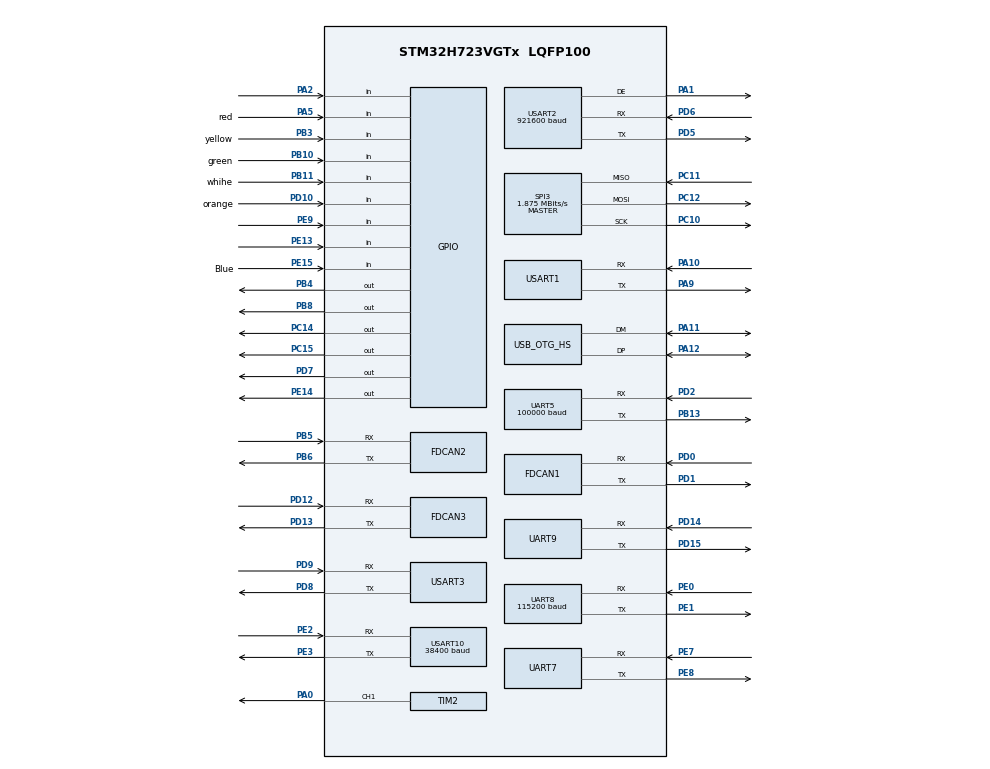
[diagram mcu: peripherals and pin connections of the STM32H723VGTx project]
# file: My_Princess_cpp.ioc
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CORTEX_M7.default_mode_Activation=1
Dma.Request0=USART2_RX
Dma.Request1=USART10_TX
Dma.Request10=TIM2_CH1
Dma.Request2=UART8_RX
Dma.Request3=UART5_RX
Dma.Request4=USART10_RX
Dma.Request5=UART9_RX
Dma.Request6=UART9_TX
Dma.Request7=UART8_TX
Dma.Request8=UART7_RX
Dma.Request9=UART7_TX
Dma.TIM2_CH1.10.Direction=DMA_MEMORY_TO_PERIPH
Dma.TIM2_CH1.10.EventEnable=DISABLE
Dma.TIM2_CH1.10.FIFOMode=DMA_FIFOMODE_DISABLE
Dma.TIM2_CH1.10.Instance=DMA2_Stream2
Dma.TIM2_CH1.10.MemDataAlignment=DMA_MDATAALIGN_WORD
Dma.TIM2_CH1.10.MemInc=DMA_MINC_ENABLE
Dma.TIM2_CH1.10.Mode=DMA_NORMAL
Dma.TIM2_CH1.10.PeriphDataAlignment=DMA_PDATAALIGN_WORD
Dma.TIM2_CH1.10.PeriphInc=DMA_PINC_DISABLE
Dma.TIM2_CH1.10.Polarity=HAL_DMAMUX_REQ_GEN_RISING
Dma.TIM2_CH1.10.Priority=DMA_PRIORITY_LOW
Dma.TIM2_CH1.10.RequestNumber=1
Dma.TIM2_CH1.10.SignalID=NONE
Dma.TIM2_CH1.10.SyncEnable=DISABLE
Dma.TIM2_CH1.10.SyncPolarity=HAL_DMAMUX_SYNC_NO_EVENT
Dma.TIM2_CH1.10.SyncRequestNumber=1
Dma.TIM2_CH1.10.SyncSignalID=NONE
Dma.UART5_RX.3.Direction=DMA_PERIPH_TO_MEMORY
Dma.UART5_RX.3.EventEnable=DISABLE
Dma.UART5_RX.3.FIFOMode=DMA_FIFOMODE_DISABLE
Dma.UART5_RX.3.Instance=DMA1_Stream0
Dma.UART5_RX.3.MemDataAlignment=DMA_MDATAALIGN_BYTE
Dma.UART5_RX.3.MemInc=DMA_MINC_ENABLE
Dma.UART5_RX.3.Mode=DMA_CIRCULAR
Dma.UART5_RX.3.PeriphDataAlignment=DMA_PDATAALIGN_BYTE
Dma.UART5_RX.3.PeriphInc=DMA_PINC_DISABLE
Dma.UART5_RX.3.Polarity=HAL_DMAMUX_REQ_GEN_RISING
Dma.UART5_RX.3.Priority=DMA_PRIORITY_HIGH
Dma.UART5_RX.3.RequestNumber=1
Dma.UART5_RX.3.SignalID=NONE
Dma.UART5_RX.3.SyncEnable=DISABLE
Dma.UART5_RX.3.SyncPolarity=HAL_DMAMUX_SYNC_NO_EVENT
Dma.UART5_RX.3.SyncRequestNumber=1
Dma.UART5_RX.3.SyncSignalID=NONE
Dma.UART7_RX.8.Direction=DMA_PERIPH_TO_MEMORY
Dma.UART7_RX.8.EventEnable=DISABLE
Dma.UART7_RX.8.FIFOMode=DMA_FIFOMODE_DISABLE
Dma.UART7_RX.8.Instance=DMA2_Stream0
Dma.UART7_RX.8.MemDataAlignment=DMA_MDATAALIGN_BYTE
Dma.UART7_RX.8.MemInc=DMA_MINC_ENABLE
Dma.UART7_RX.8.Mode=DMA_CIRCULAR
Dma.UART7_RX.8.PeriphDataAlignment=DMA_PDATAALIGN_BYTE
Dma.UART7_RX.8.PeriphInc=DMA_PINC_DISABLE
Dma.UART7_RX.8.Polarity=HAL_DMAMUX_REQ_GEN_RISING
Dma.UART7_RX.8.Priority=DMA_PRIORITY_LOW
Dma.UART7_RX.8.RequestNumber=1
Dma.UART7_RX.8.SignalID=NONE
Dma.UART7_RX.8.SyncEnable=DISABLE
Dma.UART7_RX.8.SyncPolarity=HAL_DMAMUX_SYNC_NO_EVENT
Dma.UART7_RX.8.SyncRequestNumber=1
Dma.UART7_RX.8.SyncSignalID=NONE
Dma.UART7_TX.9.Direction=DMA_MEMORY_TO_PERIPH
Dma.UART7_TX.9.EventEnable=DISABLE
Dma.UART7_TX.9.FIFOMode=DMA_FIFOMODE_DISABLE
Dma.UART7_TX.9.Instance=DMA2_Stream1
Dma.UART7_TX.9.MemDataAlignment=DMA_MDATAALIGN_BYTE
Dma.UART7_TX.9.MemInc=DMA_MINC_ENABLE
Dma.UART7_TX.9.Mode=DMA_NORMAL
Dma.UART7_TX.9.PeriphDataAlignment=DMA_PDATAALIGN_BYTE
Dma.UART7_TX.9.PeriphInc=DMA_PINC_DISABLE
Dma.UART7_TX.9.Polarity=HAL_DMAMUX_REQ_GEN_RISING
Dma.UART7_TX.9.Priority=DMA_PRIORITY_LOW
Dma.UART7_TX.9.RequestNumber=1
Dma.UART7_TX.9.SignalID=NONE
Dma.UART7_TX.9.SyncEnable=DISABLE
Dma.UART7_TX.9.SyncPolarity=HAL_DMAMUX_SYNC_NO_EVENT
Dma.UART7_TX.9.SyncRequestNumber=1
Dma.UART7_TX.9.SyncSignalID=NONE
Dma.UART8_RX.2.Direction=DMA_PERIPH_TO_MEMORY
Dma.UART8_RX.2.EventEnable=DISABLE
Dma.UART8_RX.2.FIFOMode=DMA_FIFOMODE_DISABLE
Dma.UART8_RX.2.Instance=DMA1_Stream3
Dma.UART8_RX.2.MemDataAlignment=DMA_MDATAALIGN_BYTE
Dma.UART8_RX.2.MemInc=DMA_MINC_ENABLE
Dma.UART8_RX.2.Mode=DMA_CIRCULAR
Dma.UART8_RX.2.PeriphDataAlignment=DMA_PDATAALIGN_BYTE
Dma.UART8_RX.2.PeriphInc=DMA_PINC_DISABLE
Dma.UART8_RX.2.Polarity=HAL_DMAMUX_REQ_GEN_RISING
Dma.UART8_RX.2.Priority=DMA_PRIORITY_LOW
Dma.UART8_RX.2.RequestNumber=1
Dma.UART8_RX.2.SignalID=NONE
Dma.UART8_RX.2.SyncEnable=DISABLE
Dma.UART8_RX.2.SyncPolarity=HAL_DMAMUX_SYNC_NO_EVENT
Dma.UART8_RX.2.SyncRequestNumber=1
Dma.UART8_RX.2.SyncSignalID=NONE
Dma.UART8_TX.7.Direction=DMA_MEMORY_TO_PERIPH
Dma.UART8_TX.7.EventEnable=DISABLE
Dma.UART8_TX.7.FIFOMode=DMA_FIFOMODE_DISABLE
Dma.UART8_TX.7.Instance=DMA1_Stream7
Dma.UART8_TX.7.MemDataAlignment=DMA_MDATAALIGN_BYTE
Dma.UART8_TX.7.MemInc=DMA_MINC_ENABLE
Dma.UART8_TX.7.Mode=DMA_NORMAL
Dma.UART8_TX.7.PeriphDataAlignment=DMA_PDATAALIGN_BYTE
Dma.UART8_TX.7.PeriphInc=DMA_PINC_DISABLE
Dma.UART8_TX.7.Polarity=HAL_DMAMUX_REQ_GEN_RISING
Dma.UART8_TX.7.Priority=DMA_PRIORITY_LOW
Dma.UART8_TX.7.RequestNumber=1
Dma.UART8_TX.7.SignalID=NONE
Dma.UART8_TX.7.SyncEnable=DISABLE
Dma.UART8_TX.7.SyncPolarity=HAL_DMAMUX_SYNC_NO_EVENT
Dma.UART8_TX.7.SyncRequestNumber=1
Dma.UART8_TX.7.SyncSignalID=NONE
Dma.UART9_RX.5.Direction=DMA_PERIPH_TO_MEMORY
Dma.UART9_RX.5.EventEnable=DISABLE
Dma.UART9_RX.5.FIFOMode=DMA_FIFOMODE_DISABLE
Dma.UART9_RX.5.Instance=DMA1_Stream5
Dma.UART9_RX.5.MemDataAlignment=DMA_MDATAALIGN_BYTE
Dma.UART9_RX.5.MemInc=DMA_MINC_ENABLE
Dma.UART9_RX.5.Mode=DMA_CIRCULAR
Dma.UART9_RX.5.PeriphDataAlignment=DMA_PDATAALIGN_BYTE
Dma.UART9_RX.5.PeriphInc=DMA_PINC_DISABLE
Dma.UART9_RX.5.Polarity=HAL_DMAMUX_REQ_GEN_RISING
Dma.UART9_RX.5.Priority=DMA_PRIORITY_LOW
Dma.UART9_RX.5.RequestNumber=1
Dma.UART9_RX.5.SignalID=NONE
Dma.UART9_RX.5.SyncEnable=DISABLE
Dma.UART9_RX.5.SyncPolarity=HAL_DMAMUX_SYNC_NO_EVENT
Dma.UART9_RX.5.SyncRequestNumber=1
Dma.UART9_RX.5.SyncSignalID=NONE
Dma.UART9_TX.6.Direction=DMA_MEMORY_TO_PERIPH
Dma.UART9_TX.6.EventEnable=DISABLE
Dma.UART9_TX.6.FIFOMode=DMA_FIFOMODE_DISABLE
Dma.UART9_TX.6.Instance=DMA1_Stream6
Dma.UART9_TX.6.MemDataAlignment=DMA_MDATAALIGN_BYTE
Dma.UART9_TX.6.MemInc=DMA_MINC_ENABLE
Dma.UART9_TX.6.Mode=DMA_NORMAL
Dma.UART9_TX.6.PeriphDataAlignment=DMA_PDATAALIGN_BYTE
Dma.UART9_TX.6.PeriphInc=DMA_PINC_DISABLE
Dma.UART9_TX.6.Polarity=HAL_DMAMUX_REQ_GEN_RISING
Dma.UART9_TX.6.Priority=DMA_PRIORITY_LOW
Dma.UART9_TX.6.RequestNumber=1
Dma.UART9_TX.6.SignalID=NONE
Dma.UART9_TX.6.SyncEnable=DISABLE
Dma.UART9_TX.6.SyncPolarity=HAL_DMAMUX_SYNC_NO_EVENT
Dma.UART9_TX.6.SyncRequestNumber=1
Dma.UART9_TX.6.SyncSignalID=NONE
Dma.USART10_RX.4.Direction=DMA_PERIPH_TO_MEMORY
Dma.USART10_RX.4.EventEnable=DISABLE
Dma.USART10_RX.4.FIFOMode=DMA_FIFOMODE_DISABLE
Dma.USART10_RX.4.Instance=DMA1_Stream4
Dma.USART10_RX.4.MemDataAlignment=DMA_MDATAALIGN_BYTE
Dma.USART10_RX.4.MemInc=DMA_MINC_ENABLE
Dma.USART10_RX.4.Mode=DMA_NORMAL
Dma.USART10_RX.4.PeriphDataAlignment=DMA_PDATAALIGN_BYTE
Dma.USART10_RX.4.PeriphInc=DMA_PINC_DISABLE
Dma.USART10_RX.4.Polarity=HAL_DMAMUX_REQ_GEN_RISING
Dma.USART10_RX.4.Priority=DMA_PRIORITY_LOW
Dma.USART10_RX.4.RequestNumber=1
Dma.USART10_RX.4.SignalID=NONE
Dma.USART10_RX.4.SyncEnable=DISABLE
Dma.USART10_RX.4.SyncPolarity=HAL_DMAMUX_SYNC_NO_EVENT
Dma.USART10_RX.4.SyncRequestNumber=1
Dma.USART10_RX.4.SyncSignalID=NONE
Dma.USART10_TX.1.Direction=DMA_MEMORY_TO_PERIPH
Dma.USART10_TX.1.EventEnable=DISABLE
Dma.USART10_TX.1.FIFOMode=DMA_FIFOMODE_DISABLE
Dma.USART10_TX.1.Instance=DMA1_Stream2
Dma.USART10_TX.1.MemDataAlignment=DMA_MDATAALIGN_BYTE
Dma.USART10_TX.1.MemInc=DMA_MINC_ENABLE
Dma.USART10_TX.1.Mode=DMA_NORMAL
Dma.USART10_TX.1.PeriphDataAlignment=DMA_PDATAALIGN_BYTE
Dma.USART10_TX.1.PeriphInc=DMA_PINC_DISABLE
Dma.USART10_TX.1.Polarity=HAL_DMAMUX_REQ_GEN_RISING
Dma.USART10_TX.1.Priority=DMA_PRIORITY_MEDIUM
Dma.USART10_TX.1.RequestNumber=1
Dma.USART10_TX.1.SignalID=NONE
Dma.USART10_TX.1.SyncEnable=DISABLE
Dma.USART10_TX.1.SyncPolarity=HAL_DMAMUX_SYNC_NO_EVENT
Dma.USART10_TX.1.SyncRequestNumber=1
Dma.USART10_TX.1.SyncSignalID=NONE
Dma.USART2_RX.0.Direction=DMA_PERIPH_TO_MEMORY
Dma.USART2_RX.0.EventEnable=DISABLE
Dma.USART2_RX.0.FIFOMode=DMA_FIFOMODE_DISABLE
Dma.USART2_RX.0.Instance=DMA1_Stream1
Dma.USART2_RX.0.MemDataAlignment=DMA_MDATAALIGN_BYTE
Dma.USART2_RX.0.MemInc=DMA_MINC_ENABLE
Dma.USART2_RX.0.Mode=DMA_CIRCULAR
Dma.USART2_RX.0.PeriphDataAlignment=DMA_PDATAALIGN_BYTE
Dma.USART2_RX.0.PeriphInc=DMA_PINC_DISABLE
Dma.USART2_RX.0.Polarity=HAL_DMAMUX_REQ_GEN_RISING
Dma.USART2_RX.0.Priority=DMA_PRIORITY_HIGH
Dma.USART2_RX.0.RequestNumber=1
Dma.USART2_RX.0.SignalID=NONE
Dma.USART2_RX.0.SyncEnable=DISABLE
Dma.USART2_RX.0.SyncPolarity=HAL_DMAMUX_SYNC_NO_EVENT
Dma.USART2_RX.0.SyncRequestNumber=1
Dma.USART2_RX.0.SyncSignalID=NONE
FDCAN1.CalculateBaudRateNominal=1000000
FDCAN1.CalculateTimeBitNominal=1000
FDCAN1.CalculateTimeQuantumNominal=25.0
FDCAN1.DataPrescaler=3
FDCAN1.DataSyncJumpWidth=10
FDCAN1.DataTimeSeg1=29
FDCAN1.DataTimeSeg2=5
FDCAN1.NominalPrescaler=3
FDCAN1.NominalSyncJumpWidth=10
FDCAN1.NominalTimeSeg1=29
FDCAN1.NominalTimeSeg2=10
FDCAN1.RxFifo0ElmtsNbr=8
FDCAN1.StdFiltersNbr=1
FDCAN1.TxFifoQueueElmtsNbr=8
FDCAN2.AutoRetransmission=DISABLE
FDCAN2.CalculateBaudRateNominal=1000000
FDCAN2.CalculateTimeBitNominal=1000
FDCAN2.CalculateTimeQuantumNominal=25.0
FDCAN2.DataPrescaler=3
FDCAN2.DataSyncJumpWidth=10
FDCAN2.DataTimeSeg1=29
FDCAN2.DataTimeSeg2=5
FDCAN2.ExtFiltersNbr=1
FDCAN2.MessageRAMOffset=128
FDCAN2.NominalPrescaler=3
FDCAN2.NominalSyncJumpWidth=10
FDCAN2.NominalTimeSeg1=29
FDCAN2.NominalTimeSeg2=10
FDCAN2.RxFifo0ElmtsNbr=16
FDCAN2.RxFifo1ElmtsNbr=16
FDCAN2.StdFiltersNbr=0
FDCAN2.TxFifoQueueElmtsNbr=8
FDCAN3.CalculateBaudRateNominal=1000000
FDCAN3.CalculateTimeBitNominal=1000
FDCAN3.CalculateTimeQuantumNominal=25.0
FDCAN3.DataPrescaler=3
FDCAN3.DataSyncJumpWidth=10
FDCAN3.DataTimeSeg1=29
FDCAN3.DataTimeSeg2=5
FDCAN3.MessageRAMOffset=512
FDCAN3.NominalPrescaler=3
FDCAN3.NominalSyncJumpWidth=10
FDCAN3.NominalTimeSeg1=29
FDCAN3.NominalTimeSeg2=10
FDCAN3.RxFifo0ElmtsNbr=8
FDCAN3.StdFiltersNbr=1
FDCAN3.TxFifoQueueElmtsNbr=8
FREERTOS.Tasks01=CHASSIS_TASK,24,512,chassis_task,As weak,NULL,Static,CHASSIS_TASKBuffer,CHASSIS_TASKControlBlock;USART_TASK,24,512,usart_task,As weak,NULL,Static,USART_TASKBuffer,USART_TASKControlBlock;LIFT_TASK,24,512,lift_task,As weak,NULL,Static,LIFT_TASKBuffer,LIFT_TASKControlBlock;PLAN_ROUTE,26,512,plan_route,As weak,NULL,Static,PLAN_ROUTEBuffer,PLAN_ROUTEControlBlock;FTMTask,24,512,ftm_task,As weak,NULL,Static,FTMTaskBuffer,FTMTaskControlBlock;WUQIQUTask,24,512,wuqiqu_task,As weak,NULL,Static,WUQIQUTaskBuffer,WUQIQUTaskControlBlock;CONBAT_TASK,24,512,conbat_task,As weak,NULL,Static,CONBAT_TASKBuffer,CONBAT_TASKControlBlock;LEDTask,24,256,led_task,As weak,NULL,Static,LEDTaskBuffer,LEDTaskControlBlock
Mcu.Family=STM32H7
Mcu.Name=STM32H723VGTx
Mcu.Package=LQFP100
NVIC.DMA1_Stream0_IRQn=true\:5\:0\:false\:false\:true\:true\:false\:true\:true
NVIC.DMA1_Stream1_IRQn=true\:5\:0\:false\:false\:true\:true\:false\:true\:true
NVIC.DMA1_Stream2_IRQn=true\:5\:0\:false\:false\:true\:true\:false\:true\:true
NVIC.DMA1_Stream3_IRQn=true\:5\:0\:false\:false\:true\:true\:false\:true\:true
NVIC.DMA1_Stream4_IRQn=true\:5\:0\:false\:false\:true\:true\:false\:true\:true
NVIC.DMA1_Stream5_IRQn=true\:5\:0\:false\:false\:true\:true\:false\:true\:true
NVIC.DMA1_Stream6_IRQn=true\:5\:0\:false\:false\:true\:true\:false\:true\:true
NVIC.DMA1_Stream7_IRQn=true\:5\:0\:false\:false\:true\:true\:false\:true\:true
NVIC.DMA2_Stream0_IRQn=true\:5\:0\:false\:false\:true\:true\:false\:true\:true
NVIC.DMA2_Stream1_IRQn=true\:5\:0\:false\:false\:true\:true\:false\:true\:true
NVIC.DMA2_Stream2_IRQn=true\:5\:0\:false\:false\:true\:true\:false\:true\:true
NVIC.FDCAN1_IT0_IRQn=true\:5\:0\:false\:false\:true\:true\:true\:true\:true
NVIC.FDCAN2_IT0_IRQn=true\:5\:0\:false\:false\:true\:true\:true\:true\:true
NVIC.FDCAN2_IT1_IRQn=true\:5\:0\:false\:false\:true\:true\:true\:true\:true
NVIC.FDCAN3_IT0_IRQn=true\:5\:0\:false\:false\:true\:true\:true\:true\:true
NVIC.OTG_HS_IRQn=true\:5\:0\:false\:false\:true\:true\:false\:true\:true
NVIC.PriorityGroup=NVIC_PRIORITYGROUP_4
NVIC.TIM6_DAC_IRQn=true\:15\:0\:false\:false\:true\:false\:false\:true\:true
NVIC.TimeBase=TIM6_DAC_IRQn
NVIC.TimeBaseIP=TIM6
NVIC.UART5_IRQn=true\:5\:0\:false\:false\:true\:true\:true\:true\:true
NVIC.UART7_IRQn=true\:5\:0\:false\:false\:true\:true\:true\:true\:true
NVIC.UART8_IRQn=true\:5\:0\:false\:false\:true\:true\:true\:true\:true
NVIC.UART9_IRQn=true\:5\:0\:false\:false\:true\:true\:true\:true\:true
NVIC.USART10_IRQn=true\:5\:0\:false\:false\:true\:true\:true\:true\:true
NVIC.USART2_IRQn=true\:5\:0\:false\:false\:true\:true\:true\:true\:true
PA0.Signal=S_TIM2_CH1_ETR
PA1.Mode=Hardware Flow Control (RS485)
PA1.Signal=USART2_DE
PA10.Mode=Asynchronous
PA10.Signal=USART1_RX
PA11.Mode=Device_Only_FS
PA11.Signal=USB_OTG_HS_DM
PA12.Mode=Device_Only_FS
PA12.Signal=USB_OTG_HS_DP
PA13(JTMS/SWDIO).Mode=Serial_Wire
PA13(JTMS/SWDIO).Signal=DEBUG_JTMS-SWDIO
PA14(JTCK/SWCLK).Mode=Serial_Wire
PA14(JTCK/SWCLK).Signal=DEBUG_JTCK-SWCLK
PA2.GPIO_PuPd=GPIO_PULLUP
PA2.Signal=GPIO_Input
PA5.GPIO_Label=red
PA5.GPIO_PuPd=GPIO_PULLUP
PA5.Signal=GPIO_Input
PA9.Mode=Asynchronous
PA9.Signal=USART1_TX
PB10.GPIO_Label=green
PB10.GPIO_PuPd=GPIO_PULLUP
PB10.Signal=GPIO_Input
PB11.GPIO_Label=whihe
PB11.GPIO_PuPd=GPIO_PULLUP
PB11.Signal=GPIO_Input
PB13.Mode=Asynchronous
PB13.Signal=UART5_TX
PB3(JTDO/TRACESWO).GPIO_Label=yellow
PB3(JTDO/TRACESWO).GPIO_PuPd=GPIO_PULLUP
PB3(JTDO/TRACESWO).Signal=GPIO_Input
PB4(NJTRST).Signal=GPIO_Output
PB5.Mode=FDCAN_Activate
PB5.Signal=FDCAN2_RX
PB6.Mode=FDCAN_Activate
PB6.Signal=FDCAN2_TX
PB8.PinState=GPIO_PIN_SET
PB8.Signal=GPIO_Output
PC10.Mode=Full_Duplex_Master
PC10.Signal=SPI3_SCK
PC11.Mode=Full_Duplex_Master
PC11.Signal=SPI3_MISO
PC12.Mode=Full_Duplex_Master
PC12.Signal=SPI3_MOSI
PC14-OSC32_IN.Signal=GPIO_Output
PC15-OSC32_OUT.Signal=GPIO_Output
PD0.Mode=FDCAN_Activate
PD0.Signal=FDCAN1_RX
PD1.Mode=FDCAN_Activate
PD1.Signal=FDCAN1_TX
PD10.GPIO_Label=orange
PD10.GPIO_PuPd=GPIO_PULLUP
PD10.Signal=GPIO_Input
PD12.Mode=FDCAN_Activate
PD12.Signal=FDCAN3_RX
PD13.Mode=FDCAN_Activate
PD13.Signal=FDCAN3_TX
PD14.Mode=Asynchronous
PD14.Signal=UART9_RX
PD15.Mode=Asynchronous
PD15.Signal=UART9_TX
PD2.Mode=Asynchronous
PD2.Signal=UART5_RX
PD5.Mode=Asynchronous
PD5.Signal=USART2_TX
PD6.Mode=Asynchronous
PD6.Signal=USART2_RX
PD7.Signal=GPIO_Output
PD8.Mode=Asynchronous
PD8.Signal=USART3_TX
PD9.Mode=Asynchronous
PD9.Signal=USART3_RX
PE0.Mode=Asynchronous
PE0.Signal=UART8_RX
PE1.Mode=Asynchronous
PE1.Signal=UART8_TX
PE13.GPIO_PuPd=GPIO_PULLUP
PE13.Signal=GPIO_Input
PE14.GPIO_ModeDefaultOutputPP=GPIO_MODE_OUTPUT_PP
PE14.GPIO_PuPd=GPIO_PULLUP
PE14.Signal=GPIO_Output
PE15.GPIO_Label=Blue
PE15.GPIO_PuPd=GPIO_PULLUP
PE15.Signal=GPIO_Input
PE2.Mode=Asynchronous
PE2.Signal=USART10_RX
PE3.Mode=Asynchronous
PE3.Signal=USART10_TX
PE7.Mode=Asynchronous
PE7.Signal=UART7_RX
PE8.Mode=Asynchronous
PE8.Signal=UART7_TX
PE9.GPIO_PuPd=GPIO_PULLUP
PE9.Signal=GPIO_Input
PH0-OSC_IN.Mode=HSE-External-Oscillator
PH0-OSC_IN.Signal=RCC_OSC_IN
PH1-OSC_OUT.Mode=HSE-External-Oscillator
PH1-OSC_OUT.Signal=RCC_OSC_OUT
ProjectManager.HeapSize=0x2000
ProjectManager.StackSize=0x4000
ProjectManager.TargetToolchain=MDK-ARM V5.32
RCC.ADCFreq_Value=48375000
RCC.APB1Freq_Value=120000000
RCC.APB2Freq_Value=120000000
RCC.APB3Freq_Value=120000000
RCC.APB4Freq_Value=120000000
RCC.CortexFreq_Value=480000000
RCC.D1PPRE=RCC_APB3_DIV2
RCC.D2PPRE1=RCC_APB1_DIV2
RCC.D2PPRE2=RCC_APB2_DIV2
RCC.D3PPRE=RCC_APB4_DIV2
RCC.DIVM1=2
RCC.DIVN1=40
RCC.DIVP1=1
RCC.DIVQ1=4
RCC.HCLKFreq_Value=240000000
RCC.HPRE=RCC_HCLK_DIV2
RCC.HSE_VALUE=24000000
RCC.PLL2FRACN=0
RCC.PLL3FRACN=0
RCC.PLLFRACN=0
RCC.PLLSourceVirtual=RCC_PLLSOURCE_HSE
RCC.SYSCLKFreq_VALUE=480000000
RCC.SYSCLKSource=RCC_SYSCLKSOURCE_PLLCLK
RCC.USBCLockSelection=RCC_USBCLKSOURCE_HSI48
RCC.USBFreq_Value=48000000
SH.S_TIM2_CH1_ETR.0=TIM2_CH1,PWM Generation1 CH1
SPI3.BaudRatePrescaler=SPI_BAUDRATEPRESCALER_64
SPI3.CLKPhase=SPI_PHASE_2EDGE
SPI3.CalculateBaudRate=1.875 MBits/s
SPI3.DataSize=SPI_DATASIZE_8BIT
SPI3.Direction=SPI_DIRECTION_2LINES
SPI3.Mode=SPI_MODE_MASTER
SPI3.VirtualType=VM_MASTER
STMicroelectronics.X-CUBE-ALGOBUILD.1.4.0.LibraryCcDSPOoLibraryJjDSPOoLibrary=true
TIM2.Channel-PWM\ Generation1\ CH1=TIM_CHANNEL_1
TIM2.Period=299
UART5.BaudRate=100000
UART5.Mode=MODE_RX
UART5.Parity=PARITY_EVEN
UART5.StopBits=UART_STOPBITS_2
UART5.WordLength=WORDLENGTH_9B
UART8.BaudRate=115200
USART1.VirtualMode-Asynchronous=VM_ASYNC
USART10.BaudRate=38400
USART10.VirtualMode=VM_ASYNC
USART2.BaudRate=921600
USART2.VirtualMode-Asynchronous=VM_ASYNC
USART2.VirtualMode-Hardware\ Flow\ Control\ (RS485)=VM_ASYNC
USART3.VirtualMode-Asynchronous=VM_ASYNC
USB_DEVICE.CLASS_NAME_HS=CDC
USB_DEVICE.VirtualMode=Cdc
USB_DEVICE.VirtualModeHS=Cdc_HS
USB_OTG_HS.VirtualMode-Device_Only_FS=Device_Only_FS
VP_FREERTOS_VS_CMSIS_V2.Mode=CMSIS_V2
VP_MEMORYMAP_VS_MEMORYMAP.Mode=CurAppReg
VP_STMicroelectronics.X-CUBE-ALGOBUILD_VS_DSPOoLibraryJjLibrary_1.4.0_1.4.0.Mode=DSPOoLibraryJjLibrary
VP_SYS_VS_tim6.Mode=TIM6
VP_TIM2_VS_ClockSourceINT.Mode=Internal
VP_USB_DEVICE_VS_USB_DEVICE_CDC_HS.Mode=CDC_HS
board=custom

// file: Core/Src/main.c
/* USER CODE BEGIN Header */
/**
 ******************************************************************************
 * @file           : main.c
 * @brief          : Main program body
 ******************************************************************************
 * @attention
 *
 * Copyright (c) 2026 STMicroelectronics.
 * All rights reserved.
 *
 * This software is licensed under terms that can be found in the LICENSE file
 * in the root directory of this software component.
 * If no LICENSE file comes with this software, it is provided AS-IS.
 *
 ******************************************************************************
 */
/* USER CODE END Header */
#include "main.h"
#include "cmsis_os.h"
#include "dma.h"
#include "fdcan.h"
#include "spi.h"
#include "tim.h"
#include "usart.h"
#include "usb_device.h"
#include "gpio.h"

void SystemClock_Config(void);
static void MPU_Config(void);
void MX_FREERTOS_Init(void);

int main(void)
{

  /* MPU Configuration--------------------------------------------------------*/
  MPU_Config();

  /* MCU Configuration--------------------------------------------------------*/

  /* Reset of all peripherals, Initializes the Flash interface and the Systick. */
  HAL_Init();

  /* Configure the system clock */
  SystemClock_Config();

  /* Initialize all configured peripherals */
  MX_GPIO_Init();
  MX_DMA_Init();
  MX_FDCAN1_Init();
  MX_FDCAN2_Init();
  MX_FDCAN3_Init();
  MX_UART5_Init();
  MX_UART7_Init();
  MX_UART8_Init();
  MX_USART1_UART_Init();
  MX_USART2_UART_Init();
  MX_USART3_UART_Init();
  MX_USART10_UART_Init();
  MX_SPI3_Init();
  MX_UART9_Init();
  MX_TIM2_Init();
  /* USER CODE BEGIN 2 */

  MX_USB_DEVICE_Init(); // 初始化usb
  /* USER CODE END 2 */

  /* Init scheduler */
  osKernelInitialize(); /* Call init function for freertos objects (in cmsis_os2.c) */
  MX_FREERTOS_Init();

  /* Start scheduler */
  osKernelStart();

  /* We should never get here as control is now taken by the scheduler */

  /* Infinite loop */
  while (1)
  {

  }
}

void SystemClock_Config(void)
{
  RCC_OscInitTypeDef RCC_OscInitStruct = {0};
  RCC_ClkInitTypeDef RCC_ClkInitStruct = {0};

  /** Supply configuration update enable
   */
  HAL_PWREx_ConfigSupply(PWR_LDO_SUPPLY);

  /** Configure the main internal regulator output voltage
   */
  __HAL_PWR_VOLTAGESCALING_CONFIG(PWR_REGULATOR_VOLTAGE_SCALE0);

  while (!__HAL_PWR_GET_FLAG(PWR_FLAG_VOSRDY))
  {
  }

  /** Initializes the RCC Oscillators according to the specified parameters
   * in the RCC_OscInitTypeDef structure.
   */
  RCC_OscInitStruct.OscillatorType = RCC_OSCILLATORTYPE_HSI48 | RCC_OSCILLATORTYPE_HSE;
  RCC_OscInitStruct.HSEState = RCC_HSE_ON;
  RCC_OscInitStruct.HSI48State = RCC_HSI48_ON;
  RCC_OscInitStruct.PLL.PLLState = RCC_PLL_ON;
  RCC_OscInitStruct.PLL.PLLSource = RCC_PLLSOURCE_HSE;
  RCC_OscInitStruct.PLL.PLLM = 2;
  RCC_OscInitStruct.PLL.PLLN = 40;
  RCC_OscInitStruct.PLL.PLLP = 1;
  RCC_OscInitStruct.PLL.PLLQ = 4;
  RCC_OscInitStruct.PLL.PLLR = 2;
  RCC_OscInitStruct.PLL.PLLRGE = RCC_PLL1VCIRANGE_3;
  RCC_OscInitStruct.PLL.PLLVCOSEL = RCC_PLL1VCOWIDE;
  RCC_OscInitStruct.PLL.PLLFRACN = 0;
  if (HAL_RCC_OscConfig(&RCC_OscInitStruct) != HAL_OK)
  {
    Error_Handler();
  }

  /** Initializes the CPU, AHB and APB buses clocks
   */
  RCC_ClkInitStruct.ClockType = RCC_CLOCKTYPE_HCLK | RCC_CLOCKTYPE_SYSCLK | RCC_CLOCKTYPE_PCLK1 | RCC_CLOCKTYPE_PCLK2 | RCC_CLOCKTYPE_D3PCLK1 | RCC_CLOCKTYPE_D1PCLK1;
  RCC_ClkInitStruct.SYSCLKSource = RCC_SYSCLKSOURCE_PLLCLK;
  RCC_ClkInitStruct.SYSCLKDivider = RCC_SYSCLK_DIV1;
  RCC_ClkInitStruct.AHBCLKDivider = RCC_HCLK_DIV2;
  RCC_ClkInitStruct.APB3CLKDivider = RCC_APB3_DIV2;
  RCC_ClkInitStruct.APB1CLKDivider = RCC_APB1_DIV2;
  RCC_ClkInitStruct.APB2CLKDivider = RCC_APB2_DIV2;
  RCC_ClkInitStruct.APB4CLKDivider = RCC_APB4_DIV2;

  if (HAL_RCC_ClockConfig(&RCC_ClkInitStruct, FLASH_LATENCY_3) != HAL_OK)
  {
    Error_Handler();
  }
}

/* MPU Configuration */

void MPU_Config(void)
{
  MPU_Region_InitTypeDef MPU_InitStruct = {0};

  /* Disables the MPU */
  HAL_MPU_Disable();

  /** Initializes and configures the Region and the memory to be protected
   */
  MPU_InitStruct.Enable = MPU_REGION_ENABLE;
  MPU_InitStruct.Number = MPU_REGION_NUMBER0;
  MPU_InitStruct.BaseAddress = 0x0;
  MPU_InitStruct.Size = MPU_REGION_SIZE_4GB;
  MPU_InitStruct.SubRegionDisable = 0x87;
  MPU_InitStruct.TypeExtField = MPU_TEX_LEVEL0;
  MPU_InitStruct.AccessPermission = MPU_REGION_NO_ACCESS;
  MPU_InitStruct.DisableExec = MPU_INSTRUCTION_ACCESS_DISABLE;
  MPU_InitStruct.IsShareable = MPU_ACCESS_SHAREABLE;
  MPU_InitStruct.IsCacheable = MPU_ACCESS_NOT_CACHEABLE;
  MPU_InitStruct.IsBufferable = MPU_ACCESS_NOT_BUFFERABLE;

  HAL_MPU_ConfigRegion(&MPU_InitStruct);
  /* Enables the MPU */
  HAL_MPU_Enable(MPU_PRIVILEGED_DEFAULT);
}

void HAL_TIM_PeriodElapsedCallback(TIM_HandleTypeDef *htim)
{
  if (htim->Instance == TIM6)
  {
    HAL_IncTick();
  }
}

void Error_Handler(void)
{
  __disable_irq();
  while (1)
  {
  }
}

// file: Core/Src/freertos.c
/* USER CODE BEGIN Header */
/**
  ******************************************************************************
  * File Name          : freertos.c
  * Description        : Code for freertos applications
  ******************************************************************************
  * @attention
  *
  * Copyright (c) 2026 STMicroelectronics.
  * All rights reserved.
  *
  * This software is licensed under terms that can be found in the LICENSE file
  * in the root directory of this software component.
  * If no LICENSE file comes with this software, it is provided AS-IS.
  *
  ******************************************************************************
  */
/* USER CODE END Header */

#include "FreeRTOS.h"
#include "task.h"
#include "main.h"
#include "cmsis_os.h"

typedef StaticTask_t osStaticThreadDef_t;

/* Definitions for CHASSIS_TASK */
osThreadId_t CHASSIS_TASKHandle;
uint32_t CHASSIS_TASKBuffer[ 512 ];
osStaticThreadDef_t CHASSIS_TASKControlBlock;
const osThreadAttr_t CHASSIS_TASK_attributes = {
  .name = "CHASSIS_TASK",
  .cb_mem = &CHASSIS_TASKControlBlock,
  .cb_size = sizeof(CHASSIS_TASKControlBlock),
  .stack_mem = &CHASSIS_TASKBuffer[0],
  .stack_size = sizeof(CHASSIS_TASKBuffer),
  .priority = (osPriority_t) osPriorityNormal,
};
/* Definitions for USART_TASK */
osThreadId_t USART_TASKHandle;
uint32_t USART_TASKBuffer[ 512 ];
osStaticThreadDef_t USART_TASKControlBlock;
const osThreadAttr_t USART_TASK_attributes = {
  .name = "USART_TASK",
  .cb_mem = &USART_TASKControlBlock,
  .cb_size = sizeof(USART_TASKControlBlock),
  .stack_mem = &USART_TASKBuffer[0],
  .stack_size = sizeof(USART_TASKBuffer),
  .priority = (osPriority_t) osPriorityNormal,
};
/* Definitions for LIFT_TASK */
osThreadId_t LIFT_TASKHandle;
uint32_t LIFT_TASKBuffer[ 512 ];
osStaticThreadDef_t LIFT_TASKControlBlock;
const osThreadAttr_t LIFT_TASK_attributes = {
  .name = "LIFT_TASK",
  .cb_mem = &LIFT_TASKControlBlock,
  .cb_size = sizeof(LIFT_TASKControlBlock),
  .stack_mem = &LIFT_TASKBuffer[0],
  .stack_size = sizeof(LIFT_TASKBuffer),
  .priority = (osPriority_t) osPriorityNormal,
};
/* Definitions for PLAN_ROUTE */
osThreadId_t PLAN_ROUTEHandle;
uint32_t PLAN_ROUTEBuffer[ 512 ];
osStaticThreadDef_t PLAN_ROUTEControlBlock;
const osThreadAttr_t PLAN_ROUTE_attributes = {
  .name = "PLAN_ROUTE",
  .cb_mem = &PLAN_ROUTEControlBlock,
  .cb_size = sizeof(PLAN_ROUTEControlBlock),
  .stack_mem = &PLAN_ROUTEBuffer[0],
  .stack_size = sizeof(PLAN_ROUTEBuffer),
  .priority = (osPriority_t) osPriorityNormal2,
};
/* Definitions for FTMTask */
osThreadId_t FTMTaskHandle;
uint32_t FTMTaskBuffer[ 512 ];
osStaticThreadDef_t FTMTaskControlBlock;
const osThreadAttr_t FTMTask_attributes = {
  .name = "FTMTask",
  .cb_mem = &FTMTaskControlBlock,
  .cb_size = sizeof(FTMTaskControlBlock),
  .stack_mem = &FTMTaskBuffer[0],
  .stack_size = sizeof(FTMTaskBuffer),
  .priority = (osPriority_t) osPriorityNormal,
};
/* Definitions for WUQIQUTask */
osThreadId_t WUQIQUTaskHandle;
uint32_t WUQIQUTaskBuffer[ 512 ];
osStaticThreadDef_t WUQIQUTaskControlBlock;
const osThreadAttr_t WUQIQUTask_attributes = {
  .name = "WUQIQUTask",
  .cb_mem = &WUQIQUTaskControlBlock,
  .cb_size = sizeof(WUQIQUTaskControlBlock),
  .stack_mem = &WUQIQUTaskBuffer[0],
  .stack_size = sizeof(WUQIQUTaskBuffer),
  .priority = (osPriority_t) osPriorityNormal,
};
/* Definitions for CONBAT_TASK */
osThreadId_t CONBAT_TASKHandle;
uint32_t CONBAT_TASKBuffer[ 512 ];
osStaticThreadDef_t CONBAT_TASKControlBlock;
const osThreadAttr_t CONBAT_TASK_attributes = {
  .name = "CONBAT_TASK",
  .cb_mem = &CONBAT_TASKControlBlock,
  .cb_size = sizeof(CONBAT_TASKControlBlock),
  .stack_mem = &CONBAT_TASKBuffer[0],
  .stack_size = sizeof(CONBAT_TASKBuffer),
  .priority = (osPriority_t) osPriorityNormal,
};
/* Definitions for LEDTask */
osThreadId_t LEDTaskHandle;
uint32_t LEDTaskBuffer[ 256 ];
osStaticThreadDef_t LEDTaskControlBlock;
const osThreadAttr_t LEDTask_attributes = {
  .name = "LEDTask",
  .cb_mem = &LEDTaskControlBlock,
  .cb_size = sizeof(LEDTaskControlBlock),
  .stack_mem = &LEDTaskBuffer[0],
  .stack_size = sizeof(LEDTaskBuffer),
  .priority = (osPriority_t) osPriorityNormal,
};

void chassis_task(void *argument);
void usart_task(void *argument);
void lift_task(void *argument);
void plan_route(void *argument);
void ftm_task(void *argument);
void wuqiqu_task(void *argument);
void conbat_task(void *argument);
void led_task(void *argument);

extern void MX_USB_DEVICE_Init(void);
void MX_FREERTOS_Init(void); /* (MISRA C 2004 rule 8.1) */

void MX_FREERTOS_Init(void) {

  /* Create the thread(s) */
  /* creation of CHASSIS_TASK */
  CHASSIS_TASKHandle = osThreadNew(chassis_task, NULL, &CHASSIS_TASK_attributes);

  /* creation of USART_TASK */
  USART_TASKHandle = osThreadNew(usart_task, NULL, &USART_TASK_attributes);

  /* creation of LIFT_TASK */
  LIFT_TASKHandle = osThreadNew(lift_task, NULL, &LIFT_TASK_attributes);

  /* creation of PLAN_ROUTE */
  PLAN_ROUTEHandle = osThreadNew(plan_route, NULL, &PLAN_ROUTE_attributes);

  /* creation of FTMTask */
  FTMTaskHandle = osThreadNew(ftm_task, NULL, &FTMTask_attributes);

  /* creation of WUQIQUTask */
  WUQIQUTaskHandle = osThreadNew(wuqiqu_task, NULL, &WUQIQUTask_attributes);

  /* creation of CONBAT_TASK */
  CONBAT_TASKHandle = osThreadNew(conbat_task, NULL, &CONBAT_TASK_attributes);

  /* creation of LEDTask */
  LEDTaskHandle = osThreadNew(led_task, NULL, &LEDTask_attributes);

}

__weak void chassis_task(void *argument)
{
  /* init code for USB_DEVICE */
  MX_USB_DEVICE_Init();
  for(;;)
  {
    osDelay(1);
  }
}

__weak void usart_task(void *argument)
{
  for(;;)
  {
    osDelay(1);
  }
}

__weak void lift_task(void *argument)
{
  for(;;)
  {
    osDelay(1);
  }
}

__weak void plan_route(void *argument)
{
  for(;;)
  {
    osDelay(1);
  }
}

__weak void ftm_task(void *argument)
{
  for(;;)
  {
    osDelay(1);
  }
}

__weak void wuqiqu_task(void *argument)
{
  for(;;)
  {
    osDelay(1);
  }
}

__weak void conbat_task(void *argument)
{
  for(;;)
  {
    osDelay(1);
  }
}

__weak void led_task(void *argument)
{
  for(;;)
  {
    osDelay(1);
  }
}
